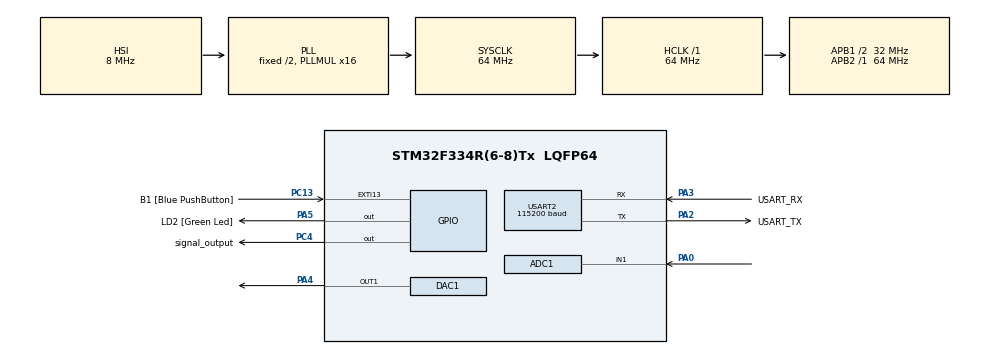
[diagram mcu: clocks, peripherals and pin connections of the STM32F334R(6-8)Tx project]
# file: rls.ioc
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ADC1.Channel-0\#ChannelRegularConversion=ADC_CHANNEL_1
ADC1.NbrOfConversionFlag=1
ADC1.Offset-0\#ChannelRegularConversion=0
ADC1.OffsetNumber-0\#ChannelRegularConversion=ADC_OFFSET_NONE
ADC1.Rank-0\#ChannelRegularConversion=1
ADC1.SamplingTime-0\#ChannelRegularConversion=ADC_SAMPLETIME_1CYCLE_5
ADC1.SamplingTimeOPAMP-0\#ChannelRegularConversion=ADC_SAMPLETIME_61CYCLES_5
ADC1.SubFamily=STM32F334x8
ADC1.master=1
DAC1.DAC_Trigger=DAC_TRIGGER_NONE
FREERTOS.Tasks01=defaultTask,0,128,StartDefaultTask,Default,NULL,Dynamic,NULL,NULL
Mcu.Family=STM32F3
Mcu.Name=STM32F334R(6-8)Tx
Mcu.Package=LQFP64
NVIC.PriorityGroup=NVIC_PRIORITYGROUP_4
NVIC.TIM6_DAC1_IRQn=true\:5\:0\:false\:false\:true\:true\:true\:true\:true
NVIC.USART2_IRQn=true\:5\:0\:false\:false\:true\:true\:true\:true\:true
PA0.Mode=IN1-Single-Ended
PA0.Signal=ADC1_IN1
PA13.GPIO_Label=TMS
PA13.Mode=Serial_Wire
PA13.Signal=SYS_JTMS-SWDIO
PA14.GPIO_Label=TCK
PA14.Mode=Serial_Wire
PA14.Signal=SYS_JTCK-SWCLK
PA2.GPIO_Label=USART_TX
PA2.Mode=Asynchronous
PA2.Signal=USART2_TX
PA3.GPIO_Label=USART_RX
PA3.Mode=Asynchronous
PA3.Signal=USART2_RX
PA4.Signal=COMP_DAC11_group
PA5.GPIO_Label=LD2 [Green Led]
PA5.Signal=GPIO_Output
PB3.GPIO_Label=SWO
PB3.Signal=SYS_JTDO-TRACESWO
PC13.GPIO_Label=B1 [Blue PushButton]
PC13.GPIO_ModeDefaultEXTI=GPIO_MODE_IT_FALLING
PC13.Signal=GPXTI13
PC14\ /\ OSC32_IN.Mode=LSE-External-Oscillator
PC14\ /\ OSC32_IN.Signal=RCC_OSC32_IN
PC15\ /\ OSC32_OUT.GPIO_Label=RCC_OSC32_OUT
PC15\ /\ OSC32_OUT.Mode=LSE-External-Oscillator
PC15\ /\ OSC32_OUT.Signal=RCC_OSC32_OUT
PC4.GPIO_Label=signal_output
PC4.Signal=GPIO_Output
PF0\ /\ OSC_IN.Mode=HSE-External-Clock-Source
PF0\ /\ OSC_IN.Signal=RCC_OSC_IN
PF1\ /\ OSC_OUT.Signal=RCC_OSC_OUT
ProjectManager.HeapSize=0x200
ProjectManager.StackSize=0x400
ProjectManager.TargetToolchain=STM32CubeIDE
RCC.AHBFreq_Value=64000000
RCC.APB1CLKDivider=RCC_HCLK_DIV2
RCC.APB1Freq_Value=32000000
RCC.APB1TimFreq_Value=64000000
RCC.APB2Freq_Value=64000000
RCC.APB2TimFreq_Value=64000000
RCC.CortexFreq_Value=64000000
RCC.FLatency-AdvancedSettings=FLASH_LATENCY_2
RCC.HCLKFreq_Value=64000000
RCC.HSE_VALUE=8000000
RCC.HSI_VALUE=8000000
RCC.PLLMUL=RCC_PLL_MUL16
RCC.SYSCLKFreq_VALUE=64000000
RCC.SYSCLKSourceVirtual=RCC_SYSCLKSOURCE_PLLCLK
SH.COMP_DAC11_group.0=DAC1_OUT1,DAC_OUT1
TIM6.AutoReloadPreload=TIM_AUTORELOAD_PRELOAD_ENABLE
TIM6.Period=200
TIM6.Prescaler=32000
TIM6.TIM_MasterOutputTrigger=TIM_TRGO_RESET
USART2.BaudRate=115200
USART2.VirtualMode-Asynchronous=VM_ASYNC
VP_FREERTOS_VS_CMSIS_V1.Mode=CMSIS_V1
VP_TIM6_VS_ClockSourceINT.Mode=Enable_Timer
board=NUCLEO-F334R8

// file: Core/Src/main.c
/* USER CODE BEGIN Header */
/**
  ******************************************************************************
  * @file           : main.c
  * @brief          : Main program body
  ******************************************************************************
  * @attention
  *
  * Copyright (c) 2023 STMicroelectronics.
  * All rights reserved.
  *
  * This software is licensed under terms that can be found in the LICENSE file
  * in the root directory of this software component.
  * If no LICENSE file comes with this software, it is provided AS-IS.
  *
  ******************************************************************************
  */
/* USER CODE END Header */
#include "main.h"
#include "cmsis_os.h"
#include "adc.h"
#include "dac.h"
#include "tim.h"
#include "usart.h"
#include "gpio.h"

/* USER CODE BEGIN Includes */
#include "app.h"
/* USER CODE END Includes */

/* USER CODE BEGIN PTD */
#define ARM_CM_DEMCR (*(uint32_t*)0xE000EDFC)
#define ARM_CM_DWT_CTRL (*(uint32_t*)0xE0001000)
#define ARM_CM_DWT_CYCCNT (*(uint32_t*)0xE0001004)
/* USER CODE END PTD */

void SystemClock_Config(void);
void MX_FREERTOS_Init(void);

int main(void)
{

  /* MCU Configuration--------------------------------------------------------*/

  /* Reset of all peripherals, Initializes the Flash interface and the Systick. */
  HAL_Init();

  /* USER CODE BEGIN Init */
  if (ARM_CM_DWT_CTRL !=0) {
	  ARM_CM_DEMCR |= 1<<24;
	  ARM_CM_DWT_CYCCNT=0;
	  ARM_CM_DWT_CTRL |= 1<<0;

}
  /* USER CODE END Init */

  /* Configure the system clock */
  SystemClock_Config();

  /* Initialize all configured peripherals */
  MX_GPIO_Init();
  MX_USART2_UART_Init();
  MX_ADC1_Init();
  MX_DAC1_Init();
  MX_TIM6_Init();
  /* USER CODE BEGIN 2 */
  app();
  /* USER CODE END 2 */

  /* Call init function for freertos objects (in freertos.c) */
  MX_FREERTOS_Init();

  /* Start scheduler */
  osKernelStart();

  /* We should never get here as control is now taken by the scheduler */
  /* Infinite loop */
  while (1)
  {

  }
}

void SystemClock_Config(void)
{
  RCC_OscInitTypeDef RCC_OscInitStruct = {0};
  RCC_ClkInitTypeDef RCC_ClkInitStruct = {0};
  RCC_PeriphCLKInitTypeDef PeriphClkInit = {0};

  /** Initializes the RCC Oscillators according to the specified parameters
  * in the RCC_OscInitTypeDef structure.
  */
  RCC_OscInitStruct.OscillatorType = RCC_OSCILLATORTYPE_HSI;
  RCC_OscInitStruct.HSIState = RCC_HSI_ON;
  RCC_OscInitStruct.HSICalibrationValue = RCC_HSICALIBRATION_DEFAULT;
  RCC_OscInitStruct.PLL.PLLState = RCC_PLL_ON;
  RCC_OscInitStruct.PLL.PLLSource = RCC_PLLSOURCE_HSI;
  RCC_OscInitStruct.PLL.PLLMUL = RCC_PLL_MUL16;
  if (HAL_RCC_OscConfig(&RCC_OscInitStruct) != HAL_OK)
  {
    Error_Handler();
  }

  /** Initializes the CPU, AHB and APB buses clocks
  */
  RCC_ClkInitStruct.ClockType = RCC_CLOCKTYPE_HCLK|RCC_CLOCKTYPE_SYSCLK
                              |RCC_CLOCKTYPE_PCLK1|RCC_CLOCKTYPE_PCLK2;
  RCC_ClkInitStruct.SYSCLKSource = RCC_SYSCLKSOURCE_PLLCLK;
  RCC_ClkInitStruct.AHBCLKDivider = RCC_SYSCLK_DIV1;
  RCC_ClkInitStruct.APB1CLKDivider = RCC_HCLK_DIV2;
  RCC_ClkInitStruct.APB2CLKDivider = RCC_HCLK_DIV1;

  if (HAL_RCC_ClockConfig(&RCC_ClkInitStruct, FLASH_LATENCY_2) != HAL_OK)
  {
    Error_Handler();
  }
  PeriphClkInit.PeriphClockSelection = RCC_PERIPHCLK_ADC12;
  PeriphClkInit.Adc12ClockSelection = RCC_ADC12PLLCLK_DIV1;
  if (HAL_RCCEx_PeriphCLKConfig(&PeriphClkInit) != HAL_OK)
  {
    Error_Handler();
  }
}

void Error_Handler(void)
{
  __disable_irq();
  while (1)
  {
  }
}
